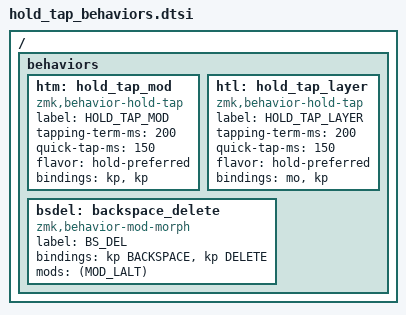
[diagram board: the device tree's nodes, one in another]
#include <behaviors.dtsi>

#define STRINGIFY(x) #x

#define LEFT_KEYS 0 1 2 3 4 10 11 12 13 14 20 21 22 23 24 25 32 33 34 35 36 37
#define RIGHT_KEYS 5 6 7 8 9 15 16 17 18 19 26 27 28 29 30 31 32 33 34 35 36 37

#define HOME_ROW_HOLD_TAP(NAME,...) \
  h##NAME: home_row_hold_tap_##NAME { \
    compatible = "zmk,behavior-hold-tap"; \
    label = STRINGIFY(home_row_ht_ ## NAME); \
    #binding-cells = <2>; \
    flavor = "tap-preferred"; \
    tapping-term-ms = <250>; \
    quick-tap-ms = <200>; \
    global-quick-tap; \
    __VA_ARGS__ \
  };

#define HOME_ROW_HOLD_TAP_L(NAME,...) \
  HOME_ROW_HOLD_TAP(NAME,hold-trigger-key-positions = <RIGHT_KEYS>; hold-trigger-on-release; __VA_ARGS__)

#define HOME_ROW_HOLD_TAP_R(NAME,...) \
  HOME_ROW_HOLD_TAP(NAME,hold-trigger-key-positions = <LEFT_KEYS>; hold-trigger-on-release; __VA_ARGS__)

#define HOME_ROW_MOD_L(NAME) \
  HOME_ROW_HOLD_TAP_L(NAME, bindings = <&kp>, <&kp>;)

#define HOME_ROW_MOD_R(NAME) \
  HOME_ROW_HOLD_TAP_R(NAME, bindings = <&kp>, <&kp>;)

#define HOME_ROW_LAYER_L(NAME) \
  HOME_ROW_HOLD_TAP_L(NAME, bindings = <&mo>, <&kp>;)

#define HOME_ROW_LAYER_R(NAME) \
  HOME_ROW_HOLD_TAP_R(NAME, bindings = <&mo>, <&kp>;)

/ {
  behaviors {
      // tap-preferred hold taps meant for alpha keys.
      HOME_ROW_MOD_L(ml)
      HOME_ROW_MOD_R(mr)
      HOME_ROW_LAYER_L(ll)
      HOME_ROW_LAYER_R(lr)

      // layer tap without hand based triggers.
      HOME_ROW_HOLD_TAP(rl, bindings = <&mo>, <&kp>;)

      // hold-preferred hold taps meant for keys where taps aren't used frequently while typing.
      htm: hold_tap_mod {
        compatible = "zmk,behavior-hold-tap";
        label = "HOLD_TAP_MOD";
        #binding-cells = <2>;
        tapping-term-ms = <200>;
        quick-tap-ms = <150>;
        flavor = "hold-preferred";
        bindings = <&kp>, <&kp>;
      };
      htl: hold_tap_layer {
        compatible = "zmk,behavior-hold-tap";
        label = "HOLD_TAP_LAYER";
        #binding-cells = <2>;
        tapping-term-ms = <200>;
        quick-tap-ms = <150>;
        flavor = "hold-preferred";
        bindings = <&mo>, <&kp>;
      };

      // mod morph to send delete on alt+backspace
      bsdel: backspace_delete {
        compatible = "zmk,behavior-mod-morph";
        label = "BS_DEL";
        #binding-cells = <0>;
        bindings = <&kp BACKSPACE>, <&kp DELETE>;
        mods = <(MOD_LALT)>;
      };
  };
};
